AUTOSAR XML (schema 4-2-2)
package /Ethernet_Cluster
  ethernet cluster EthernetCluster: baudrate=100000000, protocol-name=ETHERNET
    ethernet physical channel Eth_Network_Channel: comm-connectors=EthernetCommunicationConnector
      pdu triggering PduTriggering_TCP_RX: pdu=ISignalIPdu_TCP_RX, to MCU
      pdu triggering PduTriggering_UDP_RX: pdu=ISignalIPdu_UDP_RX, to MCU
      pdu triggering PduTriggering_UDP_TX: pdu=ISignalIPdu_UDP_TX, from MCU
      pdu triggering PduTriggering_TCP_TX: pdu=ISignalIPdu_TCP_TX, from MCU
      network endpoint NetworkEndpoint_Test
      network endpoint NetworkEndpoint_Stub
    mac multicast group MacMulticastGroup_0: mac-multicast-address=01:00:5E:00:00:01
  so ad routing group SoAdRoutingGroup_0
package /Ethernet_Cluster/Pkg_Pdus
  pdu ISignalIPdu_UDP_TX: length=4, transmission-mode-true-timing=cyclic-timing={time-offset=0.0, time-period=0.1}
    signal ISignal_UDP_TX: start 0, 256 bit, little-endian, update-indication-bit-position=-1
  pdu ISignalIPdu_UDP_RX: length=4, transmission-mode-true-timing=cyclic-timing={time-offset=0.0, time-period=0.1}
    signal ISignal_UDP_RX: start 0, 32 bit, little-endian, update-indication-bit-position=-1
  pdu ISignalIPdu_TCP_RX: length=4, transmission-mode-true-timing=cyclic-timing={time-offset=0.0, time-period=0.1}, unused-bit-pattern=0
    signal ISignal_TCP_RX: start 0, 32 bit, little-endian, update-indication-bit-position=-1
  pdu ISignalIPdu_TCP_TX: length=4, transmission-mode-true-timing=cyclic-timing={time-offset=0.0, time-period=0.1}, unused-bit-pattern=0
    signal ISignal_TCP_TX: start 0, 32 bit, little-endian, update-indication-bit-position=-1
package /Ethernet_Cluster/Pkg_Frame
  6 x ethernet frame:
    EthernetFrame_TCP_RX
      pdu to frame mapping PduToFrameMapping_0: packing-byte-order=little-endian, pdu=ISignalIPdu_TCP_RX, start-position=0
    EthernetFrame_TCP_TX
      pdu to frame mapping PduToFrameMapping_0: packing-byte-order=little-endian, pdu=ISignalIPdu_TCP_TX, start-position=0
    EthernetFrame_UDP_RX
      pdu to frame mapping PduToFrameMapping_0: packing-byte-order=opaque, pdu=ISignalIPdu_UDP_RX
    EthernetFrame_UDP_TX
      pdu to frame mapping PduToFrameMapping_0: pdu=ISignalIPdu_UDP_TX
    EthernetFrame_SOMIPxf_TCP_RX: frame-length=32
    EthernetFrame_SOMIPxf_TCP_TX: frame-length=32
package /DBC_SysDesc_XCP/Pkg_Cluster
  can cluster Can_Network_XCP: protocol-name=CAN, protocol-version=HIPBNYYYYYYYYYYYYYYYYYYYYYYYYYYYYYYYYYYYYY/4/%%%/4/'%**4YYY///
    can physical channel Can_Network_XCP_Channel: comm-connectors=Conn_Can_Network_CANNODE_1_MCU
      frame XCP_RX_Broadcast: id 0x332, to MCU, frame-length=8, can-addressing-mode=STANDARD, can-frame-rx-behavior=ANY  # 332"
        carries pdu XCP_RX_Broadcast: packing-byte-order=big-endian, start-position=7
        general purpose i pdu XCP_RX_Broadcast: category=XCP, length=8  # 332
      frame XCP_RX_CMD: id 0x333, to MCU, frame-length=8, can-addressing-mode=STANDARD, can-frame-rx-behavior=ANY  # 333"
        carries pdu XCP_RX_CMD: packing-byte-order=big-endian, start-position=7
        general purpose i pdu XCP_RX_CMD: category=XCP, length=8  # 333
      frame XCP_TX_DAQ0: id 0x778, from MCU, frame-length=8, can-addressing-mode=STANDARD
        carries pdu XCP_TX_DAQ0: packing-byte-order=big-endian, start-position=7
        general purpose i pdu XCP_TX_DAQ0: category=XCP, length=8
      frame XCP_TX_DAQ1: id 0x779, from MCU, frame-length=8, can-addressing-mode=STANDARD
        carries pdu XCP_TX_DAQ1: packing-byte-order=big-endian, start-position=7
        general purpose i pdu XCP_TX_DAQ1: category=XCP, length=8
      frame XCP_TX_DAQ2: id 0x77A, from MCU, frame-length=8, can-addressing-mode=STANDARD
        carries pdu XCP_TX_DAQ2: packing-byte-order=big-endian, start-position=7
        general purpose i pdu XCP_TX_DAQ2: category=XCP, length=8
      frame XCP_TX_RES: id 0x777, from MCU, frame-length=8, can-addressing-mode=STANDARD  # 777"
        carries pdu XCP_TX_RES: packing-byte-order=big-endian, start-position=7
        general purpose i pdu XCP_TX_RES: category=XCP, length=8  # 777
package /DBC_SysDesc_CanNetwork/Pkg_Cluster
  can cluster Can_Network: protocol-name=CAN
    can physical channel Can_Network_Channel: comm-connectors=Conn_Can_Network_CANNODE_0_MCU
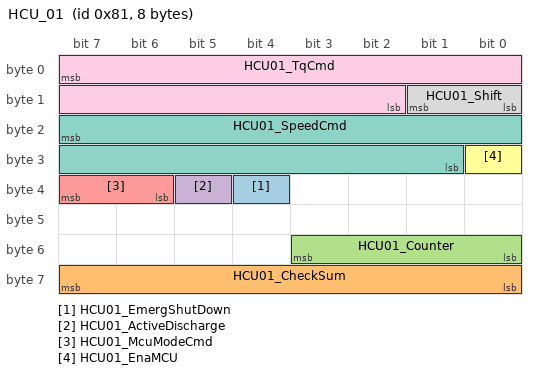
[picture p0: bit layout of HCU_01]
      frame HCU_01: id 0x81, to MCU, frame-length=8, can-addressing-mode=STANDARD, can-frame-rx-behavior=ANY
        carries pdu HCU_01: packing-byte-order=big-endian, start-position=7
        pdu HCU_01: length=8, transmission-mode-false-timing=cyclic-timing={time-offset=0.0, time-period=0.01}, transmission-mode-true-timing=cyclic-timing={time-offset=0.0, time-period=0.01}
          transmission-mode-conditions:
            {data-filter={data-filter-type=ALWAYS, max=1, min=0, offset=0}, i-signal-in-i-pdu=HCU01_EmergShutDown}
            {data-filter={data-filter-type=ALWAYS, max=255, min=0, offset=0}, i-signal-in-i-pdu=HCU01_CheckSum}
            {data-filter={data-filter-type=ALWAYS, max=15, min=0, offset=0}, i-signal-in-i-pdu=HCU01_Counter}
            {data-filter={data-filter-type=ALWAYS, max=1, min=0, offset=0}, i-signal-in-i-pdu=HCU01_ActiveDischarge}
            {data-filter={data-filter-type=ALWAYS, max=3, min=0, offset=0}, i-signal-in-i-pdu=HCU01_McuModeCmd}
            {data-filter={data-filter-type=ALWAYS, max=1, min=0, offset=0}, i-signal-in-i-pdu=HCU01_EnaMCU}
            {data-filter={data-filter-type=NEW-IS-WITHIN, max=32767, min=0}, i-signal-in-i-pdu=HCU01_SpeedCmd}
            {data-filter={data-filter-type=ALWAYS, max=3, min=0, offset=0}, i-signal-in-i-pdu=HCU01_Shift}
            {data-filter={data-filter-type=NEW-IS-WITHIN, max=16383, min=0}, i-signal-in-i-pdu=HCU01_TqCmd}
          signal HCU01_EmergShutDown: start 36, 1 bit, big-endian, init-value=0, base-type=uint8, compu {phys=raw for raw 0..1, 0=FORBIDDING, 1=ALLOWING}, update-indication-bit-position=-1, to MCU(timeout 0.3 s)  # MCUÊ¹ÄÜÐÅºÅ "
          signal HCU01_CheckSum: start 63, 8 bit, big-endian, init-value=0, base-type=uint8, compu {raw=phys for phys 0..255}, update-indication-bit-position=-1, to MCU(timeout 0.3 s)  # ¼ì²é "
          signal HCU01_Counter: start 51, 4 bit, big-endian, init-value=0, base-type=uint8, compu {raw=phys for phys 0..15}, update-indication-bit-position=-1, to MCU(timeout 0.3 s)  # ¹öÂëÐÅÏ¢ "
          signal HCU01_ActiveDischarge: start 37, 1 bit, big-endian, init-value=0, base-type=uint8, compu {phys=raw for raw 0..1, 0=FORBIDDING, 1=ALLOWING}, update-indication-bit-position=-1, to MCU(timeout 0.3 s)  # MCUÖ÷¶¯·Åµç "
          signal HCU01_McuModeCmd: start 39, 2 bit, big-endian, init-value=0, base-type=uint8, compu-method=CompuMethod_HCU01_McuModeCmd, update-indication-bit-position=-1, to MCU(timeout 0.3 s)  # µç»ú¹¤×÷Ä£Ê½ÇëÇó "
          signal HCU01_EnaMCU: start 24, 1 bit, big-endian, init-value=0, base-type=uint8, compu {phys=raw for raw 0..1, 0=FORBIDDING, 1=ALLOWING}, update-indication-bit-position=-1, to MCU(timeout 0.3 s)  # MCUÊ¹ÄÜÐÅºÅ "
          signal HCU01_SpeedCmd: start 23, 15 bit, big-endian, init-value=16384, base-type=uint16, compu {raw=phys+16384 for phys -16384..16383; unit rpm}, update-indication-bit-position=-1, to MCU(timeout 0.3 s)  # ÐèÇó×ªËÙ "
          signal HCU01_Shift: start 9, 2 bit, big-endian, init-value=0, base-type=uint8, compu {phys=raw for raw 0..3, 0=N, 1=R, 2=D, 3=P}, update-indication-bit-position=-1, to MCU(timeout 0.3 s)  # µ±Ç°Õû³µµµÎ»ÐÅÏ¢ "
          signal HCU01_TqCmd: start 7, 14 bit, big-endian, init-value=8192, base-type=uint16, compu {raw=phys*4+8192 for phys -2048..2047.75; unit Nm}, update-indication-bit-position=-1, to MCU(timeout 0.3 s)  # HCU¶ÔMCUÅ¤¾ØÇëÇó"
      frame Diag_Functional_request: id 0x7DF, to MCU, frame-length=8, can-addressing-mode=STANDARD, can-frame-rx-behavior=ANY
        carries pdu Diag_Functional_request: packing-byte-order=big-endian, start-position=7
        dcm i pdu Diag_Functional_request: length=8
      frame HCU_02: id 0x261, to MCU, frame-length=1, can-addressing-mode=STANDARD, can-frame-rx-behavior=ANY
        carries pdu HCU_02: packing-byte-order=big-endian, start-position=7
        pdu HCU_02: length=1, transmission-mode-condition{data-filter={data-filter-type=ALWAYS, max=1, min=0, offset=0}, i-signal-in-i-pdu=HCU02_Poweroff}, transmission-mode-false-timing=cyclic-timing={time-offset=0.0, time-period=0.01}, transmission-mode-true-timing=cyclic-timing={time-offset=0.0, time-period=0.01}
          signal HCU02_Poweroff: start 0, 1 bit, big-endian, init-value=0, base-type=uint8, compu {phys=raw for raw 0..1, 0=NORMAL, 1=SLEEP}, update-indication-bit-position=-1, to MCU(timeout 0.3 s)  # HCUµÍÑ¹ÏÂµç "
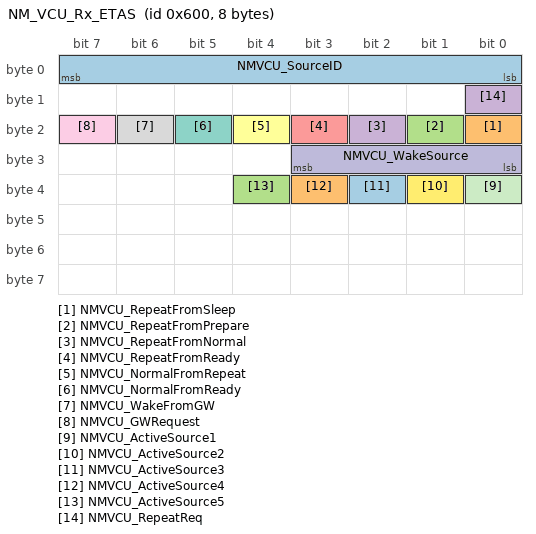
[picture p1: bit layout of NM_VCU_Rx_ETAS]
      frame NM_VCU_Rx_ETAS: id 0x600, to MCU, frame-length=8, can-addressing-mode=STANDARD, can-frame-rx-behavior=ANY
        carries pdu NM_VCU_Rx_ETAS: packing-byte-order=big-endian, start-position=7
        nm pdu NM_VCU_Rx_ETAS: length=8, nm-data-information=false, nm-vote-information=false
          signal NMVCU_SourceID: start 7, 8 bit, big-endian, init-value=0, base-type=uint8, compu {raw=phys for phys 0..255}, update-indication-bit-position=-1, to MCU  # The source node id"
          signal NMVCU_RepeatFromSleep: start 16, 1 bit, big-endian, init-value=0, base-type=uint8, compu {phys=raw for raw 0..1, 0=NOTOCCUR, 1=OCCUR}, update-indication-bit-position=-1, to MCU
          signal NMVCU_RepeatFromPrepare: start 17, 1 bit, big-endian, init-value=0, base-type=uint8, compu {phys=raw for raw 0..1, 0=NOTOCCUR, 1=OCCUR}, update-indication-bit-position=-1, to MCU
          signal NMVCU_RepeatFromNormal: start 18, 1 bit, big-endian, init-value=0, base-type=uint8, compu {phys=raw for raw 0..1, 0=NOTOCCUR, 1=OCCUR}, update-indication-bit-position=-1, to MCU
          signal NMVCU_RepeatFromReady: start 19, 1 bit, big-endian, init-value=0, base-type=uint8, compu {phys=raw for raw 0..1, 0=NOTOCCUR, 1=OCCUR}, update-indication-bit-position=-1, to MCU
          signal NMVCU_NormalFromRepeat: start 20, 1 bit, big-endian, init-value=0, base-type=uint8, compu {phys=raw for raw 0..1, 0=NOTOCCUR, 1=OCCUR}, update-indication-bit-position=-1, to MCU
          signal NMVCU_NormalFromReady: start 21, 1 bit, big-endian, init-value=0, base-type=uint8, compu {phys=raw for raw 0..1, 0=NOTOCCUR, 1=OCCUR}, update-indication-bit-position=-1, to MCU
          signal NMVCU_WakeFromGW: start 22, 1 bit, big-endian, init-value=0, base-type=uint8, compu {phys=raw for raw 0..1, 0=NOTOCCUR, 1=OCCUR}, update-indication-bit-position=-1, to MCU
          signal NMVCU_GWRequest: start 23, 1 bit, big-endian, init-value=0, base-type=uint8, compu {phys=raw for raw 0..1, 0=NOTREQUEST, 1=REQUEST}, update-indication-bit-position=-1, to MCU
          signal NMVCU_WakeSource: start 27, 4 bit, big-endian, init-value=0, base-type=uint8, compu {phys=raw for raw 0..15, 0=CANWAKEUP, 1=KL_15}, update-indication-bit-position=-1, to MCU  # The wakeup source"
          signal NMVCU_ActiveSource1: start 32, 1 bit, big-endian, init-value=0, base-type=uint8, compu {phys=raw for raw 0..1, 0=NOTACTIVE, 1=KL15}, update-indication-bit-position=-1, to MCU  # The NM active sorce is KL15"
          signal NMVCU_ActiveSource2: start 33, 1 bit, big-endian, init-value=0, base-type=uint8, compu {phys=raw for raw 0..1, 0=NOTACTIVE, 1=DIAGNOSE}, update-indication-bit-position=-1, to MCU  # The NM active sorce is Diagnose"
          signal NMVCU_ActiveSource3: start 34, 1 bit, big-endian, init-value=0, base-type=uint8, compu {phys=raw for raw 0..1, 0=NOTACTIVE, 1=REPEATMESSAGETIMERHASNOTEXPIRED}, update-indication-bit-position=-1, to MCU  # The NM active sorce is Repeat message timer has not expired"
          signal NMVCU_ActiveSource4: start 35, 1 bit, big-endian, init-value=0, base-type=uint8, compu {phys=raw for raw 0..1, 0=NOTACTIVE, 1=ACCHARGING}, update-indication-bit-position=-1, to MCU  # The NM active sorce is AC Charging"
          signal NMVCU_ActiveSource5: start 36, 1 bit, big-endian, init-value=0, base-type=uint8, compu {phys=raw for raw 0..1, 0=NOTACTIVE, 1=DCCHARGING}, update-indication-bit-position=-1, to MCU  # The NM active sorce is DC Charging"
          signal NMVCU_RepeatReq: start 8, 1 bit, big-endian, init-value=0, base-type=uint8, compu {phys=raw for raw 0..1, 0=NOTREQUEST, 1=REQUEST}, update-indication-bit-position=-1, to MCU  # The repeat message request"
      frame Diag_Physical_request: id 0x740, to MCU, frame-length=8, can-addressing-mode=STANDARD, can-frame-rx-behavior=ANY
        carries pdu Diag_Physical_request: packing-byte-order=big-endian, start-position=7
        dcm i pdu Diag_Physical_request: length=8
      frame MCU_03: id 0x106, from MCU, frame-length=8, can-addressing-mode=STANDARD
        carries pdu MCU_03: packing-byte-order=big-endian, start-position=7
        pdu MCU_03: length=8, transmission-mode-false-timing=cyclic-timing={time-offset=0.0, time-period=0.05}, transmission-mode-true-timing=cyclic-timing={time-offset=0.0, time-period=0.05}
          transmission-mode-conditions:
            {data-filter={data-filter-type=ALWAYS, max=1, min=0, offset=0}, i-signal-in-i-pdu=MCU03_LI_OverSpeed}
            {data-filter={data-filter-type=ALWAYS, max=1, min=0, offset=0}, i-signal-in-i-pdu=MCU03_LI_OverTempEM}
            {data-filter={data-filter-type=ALWAYS, max=1, min=0, offset=0}, i-signal-in-i-pdu=MCU03_LI_OverTempINV}
            {data-filter={data-filter-type=ALWAYS, max=1, min=0, offset=0}, i-signal-in-i-pdu=MCU03_LI_UdcUnder}
            {data-filter={data-filter-type=ALWAYS, max=1, min=0, offset=0}, i-signal-in-i-pdu=MCU03_LI_UdcOver}
            {data-filter={data-filter-type=ALWAYS, max=1, min=0, offset=0}, i-signal-in-i-pdu=MCU03_RF_PhaseImp}
            {data-filter={data-filter-type=ALWAYS, max=1, min=0, offset=0}, i-signal-in-i-pdu=MCU03_12VSupply}
            {data-filter={data-filter-type=ALWAYS, max=1, min=0, offset=0}, i-signal-in-i-pdu=MCU03_RF_PhCOver}
            {data-filter={data-filter-type=ALWAYS, max=1, min=0, offset=0}, i-signal-in-i-pdu=MCU03_RF_PhBOver}
            {data-filter={data-filter-type=ALWAYS, max=1, min=0, offset=0}, i-signal-in-i-pdu=MCU03_RF_PhAOver}
            {data-filter={data-filter-type=ALWAYS, max=1, min=0, offset=0}, i-signal-in-i-pdu=MCU03_RF_OverSpeed}
            {data-filter={data-filter-type=ALWAYS, max=1, min=0, offset=0}, i-signal-in-i-pdu=MCU03_RF_MsgTO}
            {data-filter={data-filter-type=ALWAYS, max=1, min=0, offset=0}, i-signal-in-i-pdu=MCU03_RF_OverTempEM}
            {data-filter={data-filter-type=ALWAYS, max=1, min=0, offset=0}, i-signal-in-i-pdu=MCU03_RF_OverTempINV}
            {data-filter={data-filter-type=ALWAYS, max=1, min=0, offset=0}, i-signal-in-i-pdu=MCU03_RF_IntError}
            {data-filter={data-filter-type=ALWAYS, max=1, min=0, offset=0}, i-signal-in-i-pdu=MCU03_RF_HWOverCur}
            {data-filter={data-filter-type=ALWAYS, max=1, min=0, offset=0}, i-signal-in-i-pdu=MCU03_RF_UDCUnder}
            {data-filter={data-filter-type=ALWAYS, max=1, min=0, offset=0}, i-signal-in-i-pdu=MCU03_RF_UdcOver}
            {data-filter={data-filter-type=ALWAYS, max=1, min=0, offset=0}, i-signal-in-i-pdu=MCU03_RF_IdcOver}
            {data-filter={data-filter-type=ALWAYS, max=1, min=0, offset=0}, i-signal-in-i-pdu=MCU03_RF_ToqError}
            {data-filter={data-filter-type=ALWAYS, max=1, min=0, offset=0}, i-signal-in-i-pdu=MCU03_RF_BusOff}
            {data-filter={data-filter-type=ALWAYS, max=1, min=0, offset=0}, i-signal-in-i-pdu=MCU03_NRF_SysFailure}
            {data-filter={data-filter-type=ALWAYS, max=1, min=0, offset=0}, i-signal-in-i-pdu=MCU03_NRF_Resolver}
            {data-filter={data-filter-type=ALWAYS, max=1, min=0, offset=0}, i-signal-in-i-pdu=MCU03_NRF_PhCSamp}
            {data-filter={data-filter-type=ALWAYS, max=1, min=0, offset=0}, i-signal-in-i-pdu=MCU03_NRF_PhBSamp}
            {data-filter={data-filter-type=ALWAYS, max=1, min=0, offset=0}, i-signal-in-i-pdu=MCU03_NRF_InvTempSamp}
            {data-filter={data-filter-type=ALWAYS, max=1, min=0, offset=0}, i-signal-in-i-pdu=MCU03_NRF_PhASamp}
            {data-filter={data-filter-type=ALWAYS, max=1, min=0, offset=0}, i-signal-in-i-pdu=MCU03_NRF_DESAT}
            {data-filter={data-filter-type=ALWAYS, max=1, min=0, offset=0}, i-signal-in-i-pdu=MCU03_NRF_UdcSamp}
            {data-filter={data-filter-type=ALWAYS, max=1, min=0, offset=0}, i-signal-in-i-pdu=MCU03_NRF_COMError}
            {data-filter={data-filter-type=ALWAYS, max=1, min=0, offset=0}, i-signal-in-i-pdu=MCU03_NRF_5VSupply}
            {data-filter={data-filter-type=ALWAYS, max=1, min=0, offset=0}, i-signal-in-i-pdu=MCU03_NRF_EMTempSamp}
            {data-filter={data-filter-type=ALWAYS, max=1, min=0, offset=0}, i-signal-in-i-pdu=MCU03_NRF_IdcSamp}
          signal MCU03_LI_OverSpeed: start 59, 1 bit, big-endian, init-value=0, base-type=uint8, compu {phys=raw for raw 0..1, 0=NOTROUBLE, 1=TROUBLE}, update-indication-bit-position=-1  # ³¬ËÙ "
          signal MCU03_LI_OverTempEM: start 58, 1 bit, big-endian, init-value=0, base-type=uint8, compu {phys=raw for raw 0..1, 0=NOTROUBLE, 1=TROUBLE}, update-indication-bit-position=-1  # µç»ú¶¨×Ó¹ýÎÂ "
          signal MCU03_LI_OverTempINV: start 57, 1 bit, big-endian, init-value=0, base-type=uint8, compu {phys=raw for raw 0..1, 0=NOTROUBLE, 1=TROUBLE}, update-indication-bit-position=-1  # Äæ±äÆ÷¹ýÎÂ "
          signal MCU03_LI_UdcUnder: start 56, 1 bit, big-endian, init-value=0, base-type=uint8, compu {phys=raw for raw 0..1, 0=NOTROUBLE, 1=TROUBLE}, update-indication-bit-position=-1  # Ä¸ÏßÇ·Ñ¹ "
          signal MCU03_LI_UdcOver: start 60, 1 bit, big-endian, init-value=0, base-type=uint8, compu {phys=raw for raw 0..1, 0=NOTROUBLE, 1=TROUBLE}, update-indication-bit-position=-1  # Ä¸Ïß¹ýÑ¹ "
          signal MCU03_RF_PhaseImp: start 39, 1 bit, big-endian, init-value=0, base-type=uint8, compu {phys=raw for raw 0..1, 0=NOTROUBLE, 1=TROUBLE}, update-indication-bit-position=-1  # ÈýÏàµçÁ÷²»Æ½ºâ "
          signal MCU03_12VSupply: start 32, 1 bit, big-endian, init-value=0, base-type=uint8, compu {phys=raw for raw 0..1, 0=NOTROUBLE, 1=TROUBLE}, update-indication-bit-position=-1  # ÈõµçµçÔ´¹ÊÕÏ "
          signal MCU03_RF_PhCOver: start 47, 1 bit, big-endian, init-value=0, base-type=uint8, compu {phys=raw for raw 0..1, 0=NOTROUBLE, 1=TROUBLE}, update-indication-bit-position=-1  # CÏà¹ýÁ÷ "
          signal MCU03_RF_PhBOver: start 46, 1 bit, big-endian, init-value=0, base-type=uint8, compu {phys=raw for raw 0..1, 0=NOTROUBLE, 1=TROUBLE}, update-indication-bit-position=-1  # BÏà¹ýÁ÷ "
          signal MCU03_RF_PhAOver: start 45, 1 bit, big-endian, init-value=0, base-type=uint8, compu {phys=raw for raw 0..1, 0=NOTROUBLE, 1=TROUBLE}, update-indication-bit-position=-1  # AÏà¹ýÁ÷ "
          signal MCU03_RF_OverSpeed: start 41, 1 bit, big-endian, init-value=0, base-type=uint8, compu {phys=raw for raw 0..1, 0=NOTROUBLE, 1=TROUBLE}, update-indication-bit-position=-1  # µç»ú¹ýËÙ "
          signal MCU03_RF_MsgTO: start 43, 1 bit, big-endian, init-value=0, base-type=uint8, compu {phys=raw for raw 0..1, 0=NOTROUBLE, 1=TROUBLE}, update-indication-bit-position=-1  # ÏûÏ¢¶ªÊ§ "
          signal MCU03_RF_OverTempEM: start 40, 1 bit, big-endian, init-value=0, base-type=uint8, compu {phys=raw for raw 0..1, 0=NOTROUBLE, 1=TROUBLE}, update-indication-bit-position=-1  # ¶¨×ÓÈÆ×é¹ýÎÂ "
          signal MCU03_RF_OverTempINV: start 36, 1 bit, big-endian, init-value=0, base-type=uint8, compu {phys=raw for raw 0..1, 0=NOTROUBLE, 1=TROUBLE}, update-indication-bit-position=-1  # Äæ±äÆ÷¹ýÎÂ "
          signal MCU03_RF_IntError: start 38, 1 bit, big-endian, init-value=0, base-type=uint8, compu {phys=raw for raw 0..1, 0=NOTROUBLE, 1=TROUBLE}, update-indication-bit-position=-1  # ³ÌÐò³¬Ê± "
          signal MCU03_RF_HWOverCur: start 44, 1 bit, big-endian, init-value=0, base-type=uint8, compu {phys=raw for raw 0..1, 0=NOTROUBLE, 1=TROUBLE}, update-indication-bit-position=-1  # ÏàµçÁ÷Ó²¼þ¼ì²â¹ýÁ÷ "
          signal MCU03_RF_UDCUnder: start 37, 1 bit, big-endian, init-value=0, base-type=uint8, compu {phys=raw for raw 0..1, 0=NOTROUBLE, 1=TROUBLE}, update-indication-bit-position=-1  # Ä¸ÏßÇ·Ñ¹ "
          signal MCU03_RF_UdcOver: start 34, 1 bit, big-endian, init-value=0, base-type=uint8, compu {phys=raw for raw 0..1, 0=NOTROUBLE, 1=TROUBLE}, update-indication-bit-position=-1  # Ä¸Ïß¹ýÑ¹ "
          signal MCU03_RF_IdcOver: start 33, 1 bit, big-endian, init-value=0, base-type=uint8, compu {phys=raw for raw 0..1, 0=NOTROUBLE, 1=TROUBLE}, update-indication-bit-position=-1  # Ä¸Ïß¹ýÁ÷ "
          signal MCU03_RF_ToqError: start 35, 1 bit, big-endian, init-value=0, base-type=uint8, compu {phys=raw for raw 0..1, 0=NOTROUBLE, 1=TROUBLE}, update-indication-bit-position=-1  # Á¦¾ØÊä³öÒì³£ "
          signal MCU03_RF_BusOff: start 42, 1 bit, big-endian, init-value=0, base-type=uint8, compu {phys=raw for raw 0..1, 0=NOTROUBLE, 1=TROUBLE}, update-indication-bit-position=-1  # CAN×ÜÏßÍ¨ÐÅÖÐ¶Ï "
          signal MCU03_NRF_SysFailure: start 11, 1 bit, big-endian, init-value=0, base-type=uint8, compu {phys=raw for raw 0..1, 0=NOTROUBLE, 1=TROUBLE}, update-indication-bit-position=-1  # ÏµÍ³Òì³£ "
          signal MCU03_NRF_Resolver: start 2, 1 bit, big-endian, init-value=0, base-type=uint8, compu {phys=raw for raw 0..1, 0=NOTROUBLE, 1=TROUBLE}, update-indication-bit-position=-1  # Ðý±ä½âÎö¹ÊÕÏ "
          signal MCU03_NRF_PhCSamp: start 5, 1 bit, big-endian, init-value=0, base-type=uint8, compu {phys=raw for raw 0..1, 0=NOTROUBLE, 1=TROUBLE}, update-indication-bit-position=-1  # CÏàµçÁ÷²ÉÑù¹ÊÕÏ "
          signal MCU03_NRF_PhBSamp: start 4, 1 bit, big-endian, init-value=0, base-type=uint8, compu {phys=raw for raw 0..1, 0=NOTROUBLE, 1=TROUBLE}, update-indication-bit-position=-1  # BÏàµçÁ÷²ÉÑù¹ÊÕÏ "
          signal MCU03_NRF_InvTempSamp: start 9, 1 bit, big-endian, init-value=0, base-type=uint8, compu {phys=raw for raw 0..1, 0=NOTROUBLE, 1=TROUBLE}, update-indication-bit-position=-1  # Äæ±äÆ÷ÎÂ¶È²ÉÑù¹ÊÕÏ "
          signal MCU03_NRF_PhASamp: start 3, 1 bit, big-endian, init-value=0, base-type=uint8, compu {phys=raw for raw 0..1, 0=NOTROUBLE, 1=TROUBLE}, update-indication-bit-position=-1  # AÏàµçÁ÷²ÉÑù¹ÊÕÏ "
          signal MCU03_NRF_DESAT: start 0, 1 bit, big-endian, init-value=0, base-type=uint8, compu {phys=raw for raw 0..1, 0=NOTROUBLE, 1=TROUBLE}, update-indication-bit-position=-1  # IGBTÍË±¥ºÍ¹ÊÕÏ "
          signal MCU03_NRF_UdcSamp: start 8, 1 bit, big-endian, init-value=0, base-type=uint8, compu {phys=raw for raw 0..1, 0=NOTROUBLE, 1=TROUBLE}, update-indication-bit-position=-1  # Ä¸ÏßµçÑ¹²ÉÑù¹ÊÕÏ "
          signal MCU03_NRF_COMError: start 10, 1 bit, big-endian, init-value=0, base-type=uint8, compu {phys=raw for raw 0..1, 0=NOTROUBLE, 1=TROUBLE}, update-indication-bit-position=-1  # Í¨Ñ¶Ä£¿é¹ÊÕÏ "
          signal MCU03_NRF_5VSupply: start 1, 1 bit, big-endian, init-value=0, base-type=uint8, compu {phys=raw for raw 0..1, 0=NOTROUBLE, 1=TROUBLE}, update-indication-bit-position=-1  # Ä£Äâ5VµçÔ´¹ÊÕÏ "
          signal MCU03_NRF_EMTempSamp: start 6, 1 bit, big-endian, init-value=0, base-type=uint8, compu {phys=raw for raw 0..1, 0=NOTROUBLE, 1=TROUBLE}, update-indication-bit-position=-1  # µç»úÎÂ¶È²ÉÑù¹ÊÕÏ "
          signal MCU03_NRF_IdcSamp: start 7, 1 bit, big-endian, init-value=0, base-type=uint8, compu {phys=raw for raw 0..1, 0=NOTROUBLE, 1=TROUBLE}, update-indication-bit-position=-1  # Ä¸ÏßµçÁ÷²ÉÑù¹ÊÕÏ "
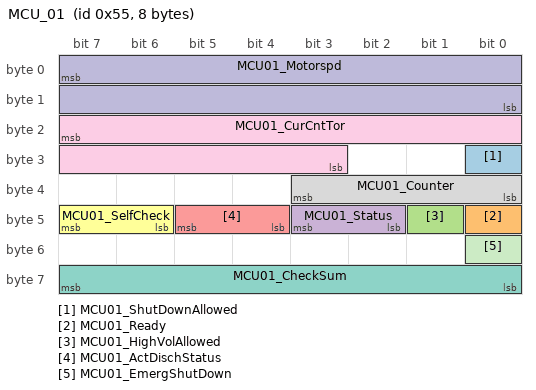
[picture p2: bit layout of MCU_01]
      frame MCU_01: id 0x55, from MCU, frame-length=8, can-addressing-mode=STANDARD
        carries pdu MCU_01: packing-byte-order=big-endian, start-position=7
        pdu MCU_01: length=8, transmission-mode-false-timing=cyclic-timing={time-offset=0.0, time-period=0.01}, transmission-mode-true-timing=cyclic-timing={time-offset=0.0, time-period=0.01}
          transmission-mode-conditions:
            {data-filter={data-filter-type=ALWAYS, max=1, min=0, offset=0}, i-signal-in-i-pdu=MCU01_ShutDownAllowed}
            {data-filter={data-filter-type=ALWAYS, max=1, min=0, offset=0}, i-signal-in-i-pdu=MCU01_Ready}
            {data-filter={data-filter-type=ALWAYS, max=1, min=0, offset=0}, i-signal-in-i-pdu=MCU01_HighVolAllowed}
            {data-filter={data-filter-type=ALWAYS, max=3, min=0, offset=0}, i-signal-in-i-pdu=MCU01_Status}
            {data-filter={data-filter-type=ALWAYS, max=3, min=0, offset=0}, i-signal-in-i-pdu=MCU01_ActDischStatus}
            {data-filter={data-filter-type=ALWAYS, max=3, min=0, offset=0}, i-signal-in-i-pdu=MCU01_SelfCheck}
            {data-filter={data-filter-type=ALWAYS, max=254, min=0, offset=0}, i-signal-in-i-pdu=MCU01_CheckSum}
            {data-filter={data-filter-type=ALWAYS, max=3, min=0, offset=0}, i-signal-in-i-pdu=MCU01_Counter}
            {data-filter={data-filter-type=NEW-IS-WITHIN, max=8189, min=0}, i-signal-in-i-pdu=MCU01_CurCntTor}
            {data-filter={data-filter-type=NEW-IS-WITHIN, max=65534, min=0}, i-signal-in-i-pdu=MCU01_Motorspd}
            {data-filter={data-filter-type=ALWAYS, max=1, min=0, offset=0}, i-signal-in-i-pdu=MCU01_EmergShutDown}
          signal MCU01_ShutDownAllowed: start 24, 1 bit, big-endian, init-value=0, base-type=uint8, compu {phys=raw for raw 0..1, 0=FORBIDDING, 1=ALLOWING}, update-indication-bit-position=-1  # ÔÊÐíÏÂµç "
          signal MCU01_Ready: start 40, 1 bit, big-endian, init-value=0, base-type=uint8, compu-method=CompuMethod_MCU01_Ready, update-indication-bit-position=-1  # ¸ßÑ¹ÉÏµçÍê³É "
          signal MCU01_HighVolAllowed: start 41, 1 bit, big-endian, init-value=0, base-type=uint8, compu {phys=raw for raw 0..1, 0=FORBIDDINGTOTURNONHV, 1=ALLOWINGTOTURNONHV}, update-indication-bit-position=-1  # ÔÊÐí¸ßÑ¹ÉÏµç "
          signal MCU01_Status: start 43, 2 bit, big-endian, init-value=0, base-type=uint8, compu-method=CompuMethod_MCU01_Status, update-indication-bit-position=-1  # µç»ú¹¤×÷×´Ì¬ "
          signal MCU01_ActDischStatus: start 45, 2 bit, big-endian, init-value=0, base-type=uint8, compu-method=CompuMethod_MCU01_ActDischStatus, update-indication-bit-position=-1  # µç»ú¿ìËÙ·Åµç×´Ì¬ "
          signal MCU01_SelfCheck: start 47, 2 bit, big-endian, init-value=0, base-type=uint8, compu {phys=raw for raw 0..3, 0=DEFAULT, 1=SELFCHECKING, 2=OK, 3=FAILED}, update-indication-bit-position=-1  # MCU×Ô¼ì "
          signal MCU01_CheckSum: start 63, 8 bit, big-endian, init-value=0, base-type=uint8, compu {raw=phys for phys 0..254}, update-indication-bit-position=-1  # ±¨ÎÄchecksum "
          signal MCU01_Counter: start 35, 4 bit, big-endian, init-value=0, base-type=uint8, compu {raw=phys for phys 0..3}, update-indication-bit-position=-1  # ±¨ÎÄ¹öÂëÐÅÏ¢ "
          signal MCU01_CurCntTor: start 23, 13 bit, big-endian, init-value=4094, base-type=uint16, compu {raw=phys*2+4094 for phys -2047..2047.5; unit Nm}, update-indication-bit-position=-1  # µç»úµ±Ç°Å¤¾Ø "
          signal MCU01_Motorspd: start 7, 16 bit, big-endian, init-value=32767, base-type=uint16, compu {raw=phys+32767 for phys -32767..32767; unit rpm}, update-indication-bit-position=-1  # µç»úµ±Ç°×ªËÙ "
          signal MCU01_EmergShutDown: start 48, 1 bit, big-endian, init-value=0, base-type=uint8, compu {phys=raw for raw 0..1, 0=NORMAL, 1=EMERGSHUTDOWN}, update-indication-bit-position=-1  # ½ô¼±ÏÂµçÇëÇó "
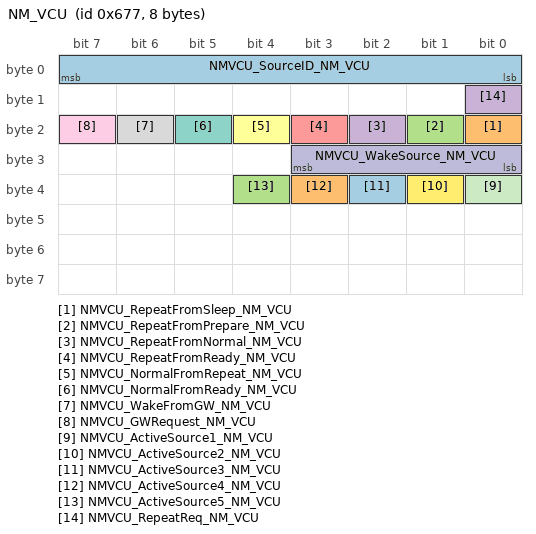
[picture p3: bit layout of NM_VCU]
      frame NM_VCU: id 0x677, from MCU, frame-length=8, can-addressing-mode=STANDARD
        carries pdu NM_VCU: packing-byte-order=big-endian, start-position=7
        nm pdu NM_VCU: length=8, nm-data-information=false, nm-vote-information=false
          signal NMVCU_SourceID_NM_VCU: start 7, 8 bit, big-endian, init-value=0, base-type=uint8, compu {raw=phys for phys 0..255}, update-indication-bit-position=-1  # The source node id"
          signal NMVCU_RepeatFromSleep_NM_VCU: start 16, 1 bit, big-endian, init-value=0, base-type=uint8, compu {phys=raw for raw 0..1, 0=NOTOCCUR, 1=OCCUR}, update-indication-bit-position=-1
          signal NMVCU_RepeatFromPrepare_NM_VCU: start 17, 1 bit, big-endian, init-value=0, base-type=uint8, compu {phys=raw for raw 0..1, 0=NOTOCCUR, 1=OCCUR}, update-indication-bit-position=-1
          signal NMVCU_RepeatFromNormal_NM_VCU: start 18, 1 bit, big-endian, init-value=0, base-type=uint8, compu {phys=raw for raw 0..1, 0=NOTOCCUR, 1=OCCUR}, update-indication-bit-position=-1
          signal NMVCU_RepeatFromReady_NM_VCU: start 19, 1 bit, big-endian, init-value=0, base-type=uint8, compu {phys=raw for raw 0..1, 0=NOTOCCUR, 1=OCCUR}, update-indication-bit-position=-1
          signal NMVCU_NormalFromRepeat_NM_VCU: start 20, 1 bit, big-endian, init-value=0, base-type=uint8, compu {phys=raw for raw 0..1, 0=NOTOCCUR, 1=OCCUR}, update-indication-bit-position=-1
          signal NMVCU_NormalFromReady_NM_VCU: start 21, 1 bit, big-endian, init-value=0, base-type=uint8, compu {phys=raw for raw 0..1, 0=NOTOCCUR, 1=OCCUR}, update-indication-bit-position=-1
          signal NMVCU_WakeFromGW_NM_VCU: start 22, 1 bit, big-endian, init-value=0, base-type=uint8, compu {phys=raw for raw 0..1, 0=NOTOCCUR, 1=OCCUR}, update-indication-bit-position=-1
          signal NMVCU_GWRequest_NM_VCU: start 23, 1 bit, big-endian, init-value=0, base-type=uint8, compu {phys=raw for raw 0..1, 0=NOTREQUEST, 1=REQUEST}, update-indication-bit-position=-1
          signal NMVCU_WakeSource_NM_VCU: start 27, 4 bit, big-endian, init-value=0, base-type=uint8, compu {phys=raw for raw 0..15, 0=CANWAKEUP, 1=KL_15}, update-indication-bit-position=-1  # The wakeup source"
          signal NMVCU_ActiveSource1_NM_VCU: start 32, 1 bit, big-endian, init-value=0, base-type=uint8, compu {phys=raw for raw 0..1, 0=NOTACTIVE, 1=KL15}, update-indication-bit-position=-1  # The NM active sorce is KL15"
          signal NMVCU_ActiveSource2_NM_VCU: start 33, 1 bit, big-endian, init-value=0, base-type=uint8, compu {phys=raw for raw 0..1, 0=NOTACTIVE, 1=DIAGNOSE}, update-indication-bit-position=-1  # The NM active sorce is Diagnose"
          signal NMVCU_ActiveSource3_NM_VCU: start 34, 1 bit, big-endian, init-value=0, base-type=uint8, compu {phys=raw for raw 0..1, 0=NOTACTIVE, 1=REPEATMESSAGETIMERHASNOTEXPIRED}, update-indication-bit-position=-1  # The NM active sorce is Repeat message timer has not expired"
          signal NMVCU_ActiveSource4_NM_VCU: start 35, 1 bit, big-endian, init-value=0, base-type=uint8, compu {phys=raw for raw 0..1, 0=NOTACTIVE, 1=ACCHARGING}, update-indication-bit-position=-1  # The NM active sorce is AC Charging"
          signal NMVCU_ActiveSource5_NM_VCU: start 36, 1 bit, big-endian, init-value=0, base-type=uint8, compu {phys=raw for raw 0..1, 0=NOTACTIVE, 1=DCCHARGING}, update-indication-bit-position=-1  # The NM active sorce is DC Charging"
          signal NMVCU_RepeatReq_NM_VCU: start 8, 1 bit, big-endian, init-value=0, base-type=uint8, compu {phys=raw for raw 0..1, 0=NOTREQUEST, 1=REQUEST}, update-indication-bit-position=-1  # The repeat message request"
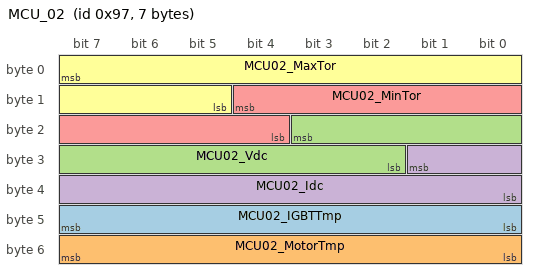
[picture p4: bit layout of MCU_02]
      frame MCU_02: id 0x97, from MCU, frame-length=7, can-addressing-mode=STANDARD
        carries pdu MCU_02: packing-byte-order=big-endian, start-position=7
        pdu MCU_02: length=7, transmission-mode-false-timing=cyclic-timing={time-offset=0.0, time-period=0.05}, transmission-mode-true-timing=cyclic-timing={time-offset=0.0, time-period=0.05}
          transmission-mode-conditions:
            {data-filter={data-filter-type=ALWAYS, max=254, min=0}, i-signal-in-i-pdu=MCU02_IGBTTmp}
            {data-filter={data-filter-type=ALWAYS, max=254, min=0}, i-signal-in-i-pdu=MCU02_MotorTmp}
            {data-filter={data-filter-type=NEW-IS-WITHIN, max=1022, min=0, offset=0}, i-signal-in-i-pdu=MCU02_Vdc}
            {data-filter={data-filter-type=NEW-IS-WITHIN, max=1022, min=0}, i-signal-in-i-pdu=MCU02_Idc}
            {data-filter={data-filter-type=NEW-IS-WITHIN, max=510, min=0, offset=0}, i-signal-in-i-pdu=MCU02_MinTor}
            {data-filter={data-filter-type=NEW-IS-WITHIN, max=2046, min=0, offset=0}, i-signal-in-i-pdu=MCU02_MaxTor}
          signal MCU02_IGBTTmp: start 47, 8 bit, big-endian, init-value=40, base-type=uint8, compu {raw=phys+40 for phys -40..214; unit deg}, update-indication-bit-position=-1  # IGBTÎÂ¶È "
          signal MCU02_MotorTmp: start 55, 8 bit, big-endian, init-value=40, base-type=uint8, compu {raw=phys+40 for phys -40..214; unit deg}, update-indication-bit-position=-1  # µç»úÎÂ¶È "
          signal MCU02_Vdc: start 19, 10 bit, big-endian, init-value=0, base-type=uint16, compu {raw=phys for phys 0..1022; unit V}, update-indication-bit-position=-1  # Ä¸ÏßµçÑ¹ "
          signal MCU02_Idc: start 25, 10 bit, big-endian, init-value=511, base-type=uint16, compu {raw=phys+511 for phys -511..511; unit Ampere}, update-indication-bit-position=-1  # Ä¸ÏßµçÁ÷ "
          signal MCU02_MinTor: start 12, 9 bit, big-endian, init-value=0, base-type=uint16, compu {raw=phys for phys 0..510; unit Nm}, update-indication-bit-position=-1  # ×îÐ¡Å¤¾Ø "
          signal MCU02_MaxTor: start 7, 11 bit, big-endian, init-value=0, base-type=uint16, compu {raw=phys for phys 0..2046; unit Nm}, update-indication-bit-position=-1  # ×î´óÅ¤¾Ø "
      frame Diag_Physical_response: id 0x748, from MCU, frame-length=8, can-addressing-mode=STANDARD
        carries pdu Diag_Physical_response: packing-byte-order=big-endian, start-position=7
        dcm i pdu Diag_Physical_response: length=8
package /DBC_SysDesc_CanNetwork/Pkg_Nm
  nm config NmConfig
    can nm cluster CanNmCluster_0: communication-cluster=Can_Network, nm-channel-id=1, nm-channel-sleep-master=false, nm-synchronizing-network=false, nm-busload-reduction-active=false, nm-car-wake-up-filter-enabled=false, nm-car-wake-up-rx-enabled=false, nm-channel-active=false
      can nm node CanNmMode_MCU_Can_Network_CANNODE_0: controller=Can_Network_CANNODE_0, nm-if-ecu=NmEcu_MCU, nm-node-id=1, nm-passive-mode-enabled=false, rx-nm-pdu=NM_VCU_Rx_ETAS, tx-nm-pdu=NM_VCU, nm-range-config={lower-can-id=1536, upper-can-id=1655}
    nm-if-ecus:
      nm ecu NmEcu_MCU:
        bus-specific-nm-ecu=can-nm-ecu=nm-repeat-msg-indication-enabled=false
        ecu-instance=MCU
        nm-bus-synchronization-enabled=false
        nm-com-control-enabled=false
        nm-coordinator=nm-node=CanNmMode_MCU_Can_Network_CANNODE_0
        nm-multiple-channels-enabled=false
        nm-node-detection-enabled=false
        nm-node-id-enabled=false
        nm-passive-mode-enabled=false
        nm-pdu-rx-indication-enabled=false
        nm-remote-sleep-ind-enabled=false
        nm-repeat-msg-ind-enabled=false
        nm-state-change-ind-enabled=false
        nm-user-data-enabled=false
package /DBC_SysDesc_CanNetwork/Pkg_Ecu
  ecu instance MCU: com-configuration-gw-time-base=0.005, com-configuration-rx-time-base=0.01, com-configuration-tx-time-base=0.01, sleep-mode-supported=false, wake-up-over-bus-supported=false
    can communication controller Can_Network_CANNODE_0: can-controller-attributes=can-controller-configuration={prop-seg=0, sync-jump-width=0, time-seg-1=10, time-seg-2=0}
    can communication controller Can_Network_CANNODE_1: can-controller-attributes=can-controller-configuration={prop-seg=1, sync-jump-width=1, time-seg-1=3, time-seg-2=3}
    ethernet communication controller EthernetCommunicationController: wake-up-by-controller-supported=false, mac-unicast-address=00:03:19:00:00:01, maximum-receive-buffer-length=1500, maximum-transmit-buffer-length=1500
      coupling port CouplingPort: connection-negotiation-behavior=MASTER, coupling-port-speed=100000000, mac-multicast-address=MacMulticastGroup_0, physical-layer-type=BROAD-R-REACH, vlan-membership=Eth_Network_Channel
    can communication connector Conn_Can_Network_CANNODE_0_MCU: comm-controller=Can_Network_CANNODE_0
    can communication connector Conn_Can_Network_CANNODE_1_MCU: comm-controller=Can_Network_CANNODE_1
    ethernet communication connector EthernetCommunicationConnector
package /DBC_SysDesc_CanNetwork/Pkg_Units
  5 x unit:
    V
    Nm
    Ampere
    deg
    rpm
package /DBC_SysDesc_CanNetwork/Pkg_CompuMethod
  compu method CompuMethod_MCU01_Status: phys=raw for raw 0..3, 0=NORMAL, 1=WARNING_DERATING, 2=RECOVERABLEFAULT, 3=NORECOVERABLEFAULT
  compu method CompuMethod_MCU01_Ready: phys=raw for raw 0..1, 0=FORBIDDINGGETTINGTORQUECMD, 1=ALLOWMCUTOGETTORQUECOMMAND
  compu method CompuMethod_HCU01_McuModeCmd: phys=raw for raw 0..3, 0=DEFAULT, 1=TORQUEMODE, 2=SPEEDMODE, 3=RESERVED
  compu method CompuMethod_MCU01_ActDischStatus: phys=raw for raw 0..3, 0=DEFAULT, 1=DISCHARGING, 2=DISCHARGEFINISHED, 3=RESERVED
package /System
  system System: category=SYSTEM_EXTRACT
    system mapping SystemMapping
      data-mappings:
        data-element=CPT_ASW_ETH.RootSwCompositionPrototype.PPort_SystemSignal_TCP_TX.PPort_SystemSignal_TCP_TX, system-signal=SystemSignal_TCP_TX
        data-element=CPT_ASW_ETH.RootSwCompositionPrototype.PPort_SystemSignal_UDP_TX.PPort_SystemSignal_UDP_TX, system-signal=SystemSignal_UDP_TX
        data-element=CPT_ASW_ETH.RootSwCompositionPrototype.RPort_SystemSignal_TCP_RX.RPort_SystemSignal_TCP_RX, system-signal=SystemSignal_TCP_RX
        data-element=CPT_ASW_ETH.RootSwCompositionPrototype.RPort_SystemSignal_UDP_RX.RPort_SystemSignal_UDP_RX, system-signal=SystemSignal_UDP_RX
        data-element=CPT_ASW_COM.RootSwCompositionPrototype.PPort_MCU03_RF_HWOverCur.MCU03_RF_HWOverCur, system-signal=MCU03_RF_HWOverCur
        data-element=CPT_ASW_COM.RootSwCompositionPrototype.PPort_MCU03_RF_ToqError.MCU03_RF_ToqError, system-signal=MCU03_RF_ToqError
        data-element=CPT_ASW_COM.RootSwCompositionPrototype.PPort_MCU03_NRF_SysFailure.MCU03_NRF_SysFailure, system-signal=MCU03_NRF_SysFailure
        data-element=CPT_ASW_COM.RootSwCompositionPrototype.PPort_MCU03_NRF_UdcSamp.MCU03_NRF_UdcSamp, system-signal=MCU03_NRF_UdcSamp
        data-element=CPT_ASW_COM.RootSwCompositionPrototype.PPort_MCU03_LI_OverSpeed.MCU03_LI_OverSpeed, system-signal=MCU03_LI_OverSpeed
        data-element=CPT_ASW_COM.RootSwCompositionPrototype.PPort_MCU02_Vdc.MCU02_Vdc, system-signal=MCU02_Vdc
        data-element=CPT_ASW_COM.RootSwCompositionPrototype.PPort_MCU03_NRF_Resolver.MCU03_NRF_Resolver, system-signal=MCU03_NRF_Resolver
        data-element=CPT_ASW_COM.RootSwCompositionPrototype.PPort_MCU03_RF_OverTempEM.MCU03_RF_OverTempEM, system-signal=MCU03_RF_OverTempEM
        data-element=CPT_ASW_COM.RootSwCompositionPrototype.RPort_HCU01_Shift.HCU01_Shift, system-signal=HCU01_Shift
        data-element=CPT_ASW_COM.RootSwCompositionPrototype.PPort_MCU03_RF_PhBOver.MCU03_RF_PhBOver, system-signal=MCU03_RF_PhBOver
        data-element=CPT_ASW_COM.RootSwCompositionPrototype.PPort_MCU03_12VSupply.MCU03_12VSupply, system-signal=MCU03_12VSupply
        data-element=CPT_ASW_COM.RootSwCompositionPrototype.PPort_MCU01_CurCntTor.MCU01_CurCntTor, system-signal=MCU01_CurCntTor
        data-element=CPT_ASW_COM.RootSwCompositionPrototype.PPort_MCU03_RF_MsgTO.MCU03_RF_MsgTO, system-signal=MCU03_RF_MsgTO
        data-element=CPT_ASW_COM.RootSwCompositionPrototype.PPort_MCU03_NRF_PhCSamp.MCU03_NRF_PhCSamp, system-signal=MCU03_NRF_PhCSamp
        data-element=CPT_ASW_COM.RootSwCompositionPrototype.PPort_MCU02_MinTor.MCU02_MinTor, system-signal=MCU02_MinTor
        data-element=CPT_ASW_COM.RootSwCompositionPrototype.PPort_MCU01_ActDischStatus.MCU01_ActDischStatus, system-signal=MCU01_ActDischStatus
        data-element=CPT_ASW_COM.RootSwCompositionPrototype.RPort_HCU02_Poweroff.HCU02_Poweroff, system-signal=HCU02_Poweroff
        data-element=CPT_ASW_COM.RootSwCompositionPrototype.RPort_HCU01_CheckSum.HCU01_CheckSum, system-signal=HCU01_CheckSum
        data-element=CPT_ASW_COM.RootSwCompositionPrototype.RPort_HCU01_EmergShutDown.HCU01_EmergShutDown, system-signal=HCU01_EmergShutDown
        data-element=CPT_ASW_COM.RootSwCompositionPrototype.PPort_MCU02_MaxTor.MCU02_MaxTor, system-signal=MCU02_MaxTor
        data-element=CPT_ASW_COM.RootSwCompositionPrototype.RPort_HCU01_TqCmd.HCU01_TqCmd, system-signal=HCU01_TqCmd
        data-element=CPT_ASW_COM.RootSwCompositionPrototype.PPort_MCU01_Counter.MCU01_Counter, system-signal=MCU01_Counter
        data-element=CPT_ASW_COM.RootSwCompositionPrototype.PPort_MCU03_RF_IdcOver.MCU03_RF_IdcOver, system-signal=MCU03_RF_IdcOver
        data-element=CPT_ASW_COM.RootSwCompositionPrototype.PPort_MCU01_EmergShutDown.MCU01_EmergShutDown, system-signal=MCU01_EmergShutDown
        data-element=CPT_ASW_COM.RootSwCompositionPrototype.PPort_MCU03_LI_UdcOver.MCU03_LI_UdcOver, system-signal=MCU03_LI_UdcOver
        data-element=CPT_ASW_COM.RootSwCompositionPrototype.PPort_MCU03_RF_OverTempINV.MCU03_RF_OverTempINV, system-signal=MCU03_RF_OverTempINV
        data-element=CPT_ASW_COM.RootSwCompositionPrototype.PPort_MCU03_NRF_PhASamp.MCU03_NRF_PhASamp, system-signal=MCU03_NRF_PhASamp
        data-element=CPT_ASW_COM.RootSwCompositionPrototype.PPort_MCU03_LI_UdcUnder.MCU03_LI_UdcUnder, system-signal=MCU03_LI_UdcUnder
        data-element=CPT_ASW_COM.RootSwCompositionPrototype.PPort_MCU03_NRF_InvTempSamp.MCU03_NRF_InvTempSamp, system-signal=MCU03_NRF_InvTempSamp
        data-element=CPT_ASW_COM.RootSwCompositionPrototype.PPort_MCU03_NRF_5VSupply.MCU03_NRF_5VSupply, system-signal=MCU03_NRF_5VSupply
        data-element=CPT_ASW_COM.RootSwCompositionPrototype.RPort_HCU01_SpeedCmd.HCU01_SpeedCmd, system-signal=HCU01_SpeedCmd
        data-element=CPT_ASW_COM.RootSwCompositionPrototype.PPort_MCU03_NRF_COMError.MCU03_NRF_COMError, system-signal=MCU03_NRF_COMError
        data-element=CPT_ASW_COM.RootSwCompositionPrototype.RPort_HCU01_EnaMCU.HCU01_EnaMCU, system-signal=HCU01_EnaMCU
        data-element=CPT_ASW_COM.RootSwCompositionPrototype.PPort_MCU01_Status.MCU01_Status, system-signal=MCU01_Status
        data-element=CPT_ASW_COM.RootSwCompositionPrototype.PPort_MCU03_RF_IntError.MCU03_RF_IntError, system-signal=MCU03_RF_IntError
        data-element=CPT_ASW_COM.RootSwCompositionPrototype.PPort_MCU03_LI_OverTempINV.MCU03_LI_OverTempINV, system-signal=MCU03_LI_OverTempINV
        data-element=CPT_ASW_COM.RootSwCompositionPrototype.PPort_MCU03_RF_PhAOver.MCU03_RF_PhAOver, system-signal=MCU03_RF_PhAOver
        data-element=CPT_ASW_COM.RootSwCompositionPrototype.PPort_MCU03_RF_OverSpeed.MCU03_RF_OverSpeed, system-signal=MCU03_RF_OverSpeed
        data-element=CPT_ASW_COM.RootSwCompositionPrototype.PPort_MCU03_NRF_DESAT.MCU03_NRF_DESAT, system-signal=MCU03_NRF_DESAT
        data-element=CPT_ASW_COM.RootSwCompositionPrototype.RPort_HCU01_McuModeCmd.HCU01_McuModeCmd, system-signal=HCU01_McuModeCmd
        data-element=CPT_ASW_COM.RootSwCompositionPrototype.PPort_MCU03_RF_PhCOver.MCU03_RF_PhCOver, system-signal=MCU03_RF_PhCOver
        data-element=CPT_ASW_COM.RootSwCompositionPrototype.PPort_MCU03_NRF_EMTempSamp.MCU03_NRF_EMTempSamp, system-signal=MCU03_NRF_EMTempSamp
        data-element=CPT_ASW_COM.RootSwCompositionPrototype.PPort_MCU03_NRF_PhBSamp.MCU03_NRF_PhBSamp, system-signal=MCU03_NRF_PhBSamp
        data-element=CPT_ASW_COM.RootSwCompositionPrototype.PPort_MCU01_Motorspd.MCU01_Motorspd, system-signal=MCU01_Motorspd
        data-element=CPT_ASW_COM.RootSwCompositionPrototype.PPort_MCU03_RF_UDCUnder.MCU03_RF_UDCUnder, system-signal=MCU03_RF_UDCUnder
        data-element=CPT_ASW_COM.RootSwCompositionPrototype.PPort_MCU02_MotorTmp.MCU02_MotorTmp, system-signal=MCU02_MotorTmp
        data-element=CPT_ASW_COM.RootSwCompositionPrototype.RPort_HCU01_ActiveDischarge.HCU01_ActiveDischarge, system-signal=HCU01_ActiveDischarge
        data-element=CPT_ASW_COM.RootSwCompositionPrototype.PPort_MCU03_RF_UdcOver.MCU03_RF_UdcOver, system-signal=MCU03_RF_UdcOver
        data-element=CPT_ASW_COM.RootSwCompositionPrototype.PPort_MCU01_CheckSum.MCU01_CheckSum, system-signal=MCU01_CheckSum
        data-element=CPT_ASW_COM.RootSwCompositionPrototype.PPort_MCU03_RF_PhaseImp.MCU03_RF_PhaseImp, system-signal=MCU03_RF_PhaseImp
        data-element=CPT_ASW_COM.RootSwCompositionPrototype.PPort_MCU01_SelfCheck.MCU01_SelfCheck, system-signal=MCU01_SelfCheck
        data-element=CPT_ASW_COM.RootSwCompositionPrototype.PPort_MCU03_RF_BusOff.MCU03_RF_BusOff, system-signal=MCU03_RF_BusOff
        data-element=CPT_ASW_COM.RootSwCompositionPrototype.PPort_MCU02_IGBTTmp.MCU02_IGBTTmp, system-signal=MCU02_IGBTTmp
        data-element=CPT_ASW_COM.RootSwCompositionPrototype.PPort_MCU03_LI_OverTempEM.MCU03_LI_OverTempEM, system-signal=MCU03_LI_OverTempEM
        data-element=CPT_ASW_COM.RootSwCompositionPrototype.PPort_MCU01_ShutDownAllowed.MCU01_ShutDownAllowed, system-signal=MCU01_ShutDownAllowed
        data-element=CPT_ASW_COM.RootSwCompositionPrototype.PPort_MCU02_Idc.MCU02_Idc, system-signal=MCU02_Idc
        data-element=CPT_ASW_COM.RootSwCompositionPrototype.PPort_MCU01_Ready.MCU01_Ready, system-signal=MCU01_Ready
        data-element=CPT_ASW_COM.RootSwCompositionPrototype.PPort_MCU03_NRF_IdcSamp.MCU03_NRF_IdcSamp, system-signal=MCU03_NRF_IdcSamp
        data-element=CPT_ASW_COM.RootSwCompositionPrototype.PPort_MCU01_HighVolAllowed.MCU01_HighVolAllowed, system-signal=MCU01_HighVolAllowed
        data-element=CPT_ASW_COM.RootSwCompositionPrototype.RPort_HCU01_Counter.HCU01_Counter, system-signal=HCU01_Counter
      sw-mappings:
        swc to ecu mapping SwcToEcuMapping_0: ecu-instance=MCU
          component:
            RootSwCompositionPrototype.CPT_ASW_COM
            RootSwCompositionPrototype.CPT_ASW_NM
            RootSwCompositionPrototype.CPT_ASW_NVM
            RootSwCompositionPrototype.CPT_BswM
            RootSwCompositionPrototype.CPT_ComM
            RootSwCompositionPrototype.CPT_Dcm
            RootSwCompositionPrototype.CPT_Dem
            RootSwCompositionPrototype.CPT_Det
            RootSwCompositionPrototype.CPT_EcuM
            RootSwCompositionPrototype.CPT_NvM
            RootSwCompositionPrototype.CPT_WdgM
            RootSwCompositionPrototype.CPT_XCP
            RootSwCompositionPrototype.CPT_ASW_CORE1
            RootSwCompositionPrototype.CPT_ASW_CORE2
            RootSwCompositionPrototype.CPT_IoHwAb_ADC
            RootSwCompositionPrototype.CPT_IoHwAb_DIO
            RootSwCompositionPrototype.CPT_SensorActuator_ADC
            RootSwCompositionPrototype.CPT_SensorActuator_DIO
            RootSwCompositionPrototype.CPT_IoHwAb_ICU
            RootSwCompositionPrototype.CPT_IoHwAb_PWM
            RootSwCompositionPrototype.CPT_SensorActuator_ICU
            RootSwCompositionPrototype.CPT_SensorActuator_PWM
            RootSwCompositionPrototype.CPT_rba_DiagLib
            RootSwCompositionPrototype.CPT_ASW_CORE0
            RootSwCompositionPrototype.CPT_ASW_CORE{3..5}
            RootSwCompositionPrototype.CPT_ASW_DEM
            RootSwCompositionPrototype.CPT_ASW_DCM
            RootSwCompositionPrototype.CPT_ASW_WDG
            RootSwCompositionPrototype.CPT_CDD_CORE{0..5}
            RootSwCompositionPrototype.CPT_ASW_ETH
            RootSwCompositionPrototype.CPT_DoIP
            RootSwCompositionPrototype.CPT_ASW_StbM
            RootSwCompositionPrototype.CPT_StbM
            RootSwCompositionPrototype.CPT_IoHwAb_DIO_Test
            RootSwCompositionPrototype.CPT_SensorActuator_DIO_Test
    root-software-compositions:
      root sw composition prototype RootSwCompositionPrototype: software-composition=Composition
